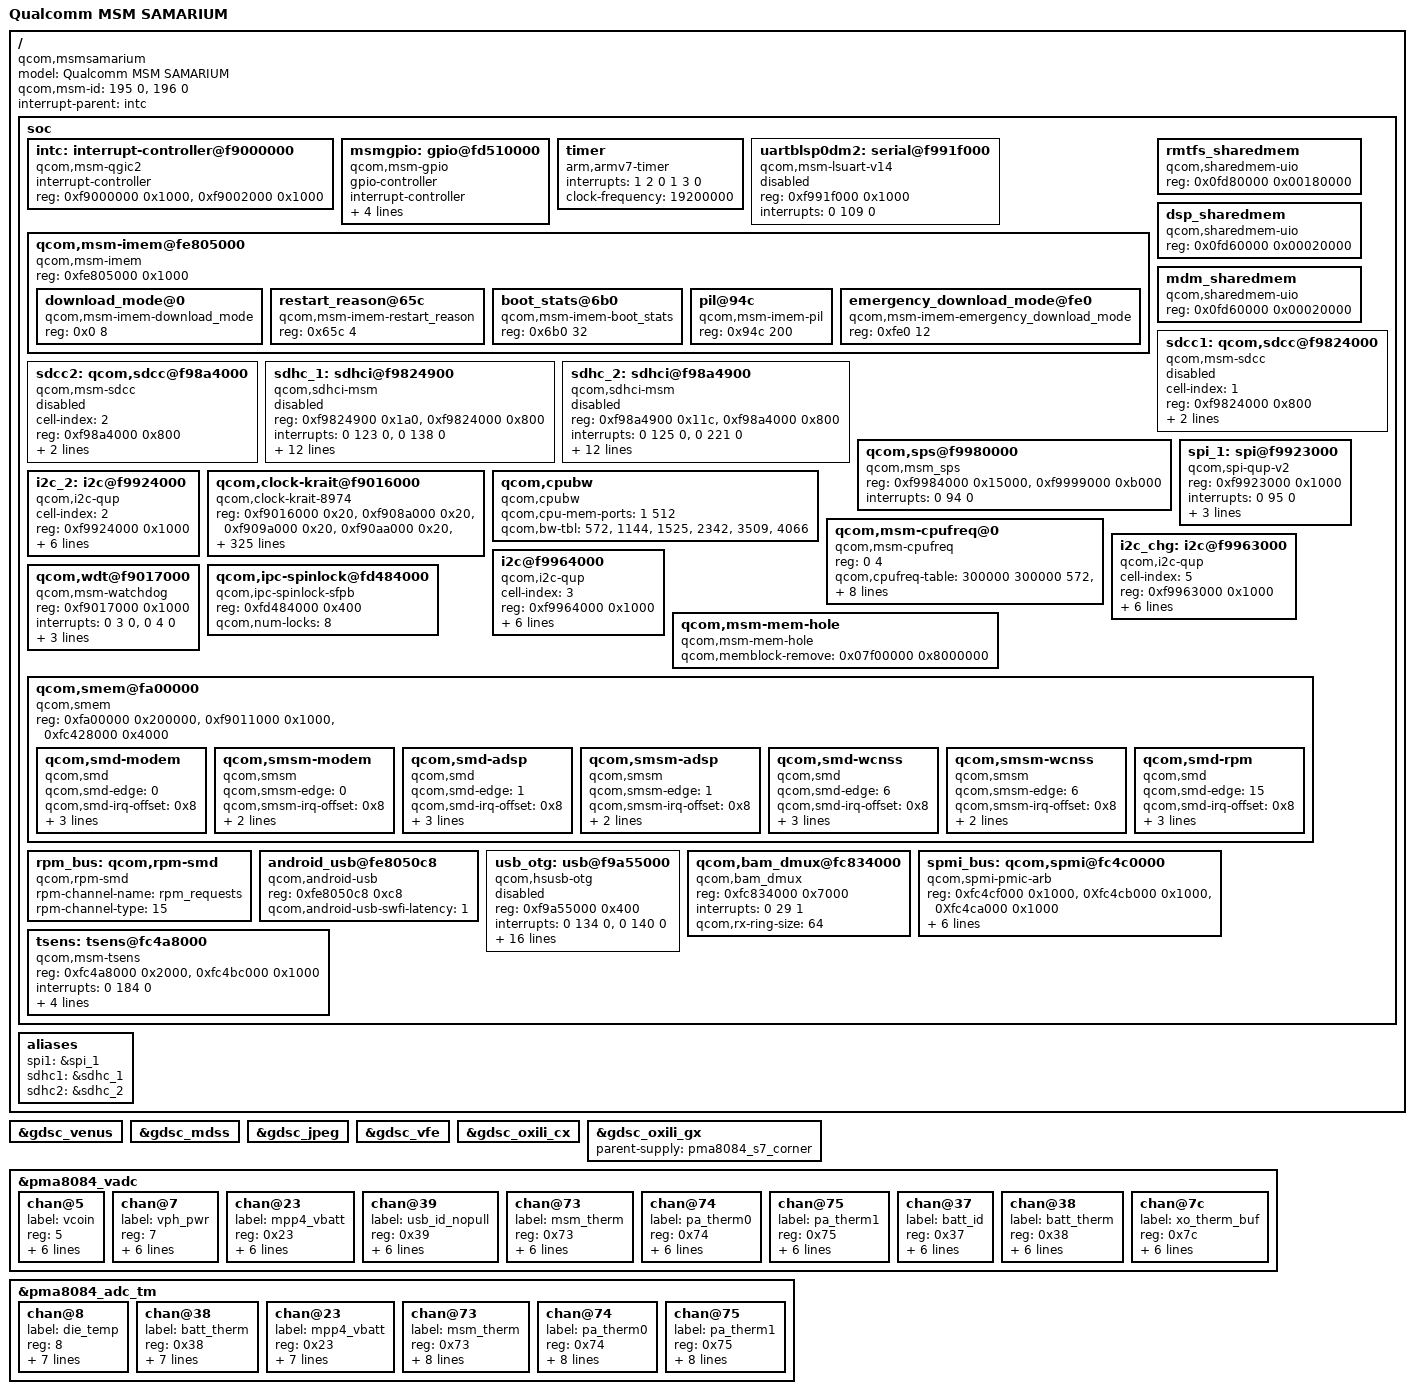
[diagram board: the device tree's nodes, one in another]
/* Copyright (c) 2013-2014, The Linux Foundation. All rights reserved.
 *
 * This program is free software; you can redistribute it and/or modify
 * it under the terms of the GNU General Public License version 2 and
 * only version 2 as published by the Free Software Foundation.
 *
 * This program is distributed in the hope that it will be useful,
 * but WITHOUT ANY WARRANTY; without even the implied warranty of
 * MERCHANTABILITY or FITNESS FOR A PARTICULAR PURPOSE.  See the
 * GNU General Public License for more details.
 */

#include "skeleton.dtsi"

/ {
	model = "Qualcomm MSM SAMARIUM";
	compatible = "qcom,msmsamarium";
	qcom,msm-id = <195 0>,
		      <196 0>;
	interrupt-parent = <&intc>;
	soc: soc { };
	aliases {
		spi1 = &spi_1;
		sdhc1 = &sdhc_1; /* SDC1 eMMC slot */
		sdhc2 = &sdhc_2; /* SDC2 SD card slot */
	};

};

#include "msm-gdsc.dtsi"
#include "msmsamarium-ion.dtsi"
#include "msmsamarium-iommu.dtsi"
#include "msmsamarium-smp2p.dtsi"
#include "msmsamarium-pm.dtsi"
#include "msmsamarium-coresight.dtsi"
#include "msmsamarium-pinctrl.dtsi"
#include "msmsamarium-bus.dtsi"
#include "msmsamarium-gpu.dtsi"
#include "msmsamarium-iommu-domains.dtsi"

&soc {
	#address-cells = <1>;
	#size-cells = <1>;
	ranges;

	intc: interrupt-controller@f9000000 {
		compatible = "qcom,msm-qgic2";
		interrupt-controller;
		#interrupt-cells = <3>;
		reg = <0xf9000000 0x1000>,
		      <0xf9002000 0x1000>;
	};

	msmgpio: gpio@fd510000 {
		compatible = "qcom,msm-gpio";
		gpio-controller;
		#gpio-cells = <2>;
		interrupt-controller;
		#interrupt-cells = <2>;
		reg = <0xfd510000 0x4000>;
		ngpio = <146>;
		interrupts = <0 208 0>;
		qcom,direct-connect-irqs = <8>;
	};

	timer {
		compatible = "arm,armv7-timer";
		interrupts = <1 2 0 1 3 0>;
		clock-frequency = <19200000>;
	};

	uartblsp0dm2: serial@f991f000 {
		compatible = "qcom,msm-lsuart-v14";
		reg = <0xf991f000 0x1000>;
		interrupts = <0 109 0>;
		status = "disabled";
	};

	qcom,msm-imem@fe805000 {
		compatible = "qcom,msm-imem";
		reg = <0xfe805000 0x1000>; /* Address and size of IMEM */
		ranges = <0x0 0xfe805000 0x1000>;
		#address-cells = <1>;
		#size-cells = <1>;

		download_mode@0 {
			compatible = "qcom,msm-imem-download_mode";
			reg = <0x0 8>;
		};

		restart_reason@65c {
			compatible = "qcom,msm-imem-restart_reason";
			reg = <0x65c 4>;
		};

		boot_stats@6b0 {
			compatible = "qcom,msm-imem-boot_stats";
			reg = <0x6b0 32>;
		};

		pil@94c {
			compatible = "qcom,msm-imem-pil";
			reg = <0x94c 200>;
		};

		emergency_download_mode@fe0 {
			compatible = "qcom,msm-imem-emergency_download_mode";
			reg = <0xfe0 12>;
		};
	};

	rmtfs_sharedmem {
		compatible = "qcom,sharedmem-uio";
		reg = <0x0fd80000 0x00180000>;
		reg-names = "rmtfs";
	};

	dsp_sharedmem {
		compatible = "qcom,sharedmem-uio";
		reg = <0x0fd60000 0x00020000>;
		reg-names = "rfsa_dsp";
	};

	mdm_sharedmem {
		compatible = "qcom,sharedmem-uio";
		reg = <0x0fd60000 0x00020000>;
		reg-names = "rfsa_mdm";
	};

	sdcc1: qcom,sdcc@f9824000 {
		cell-index = <1>; /* SDC1 eMMC slot */
		compatible = "qcom,msm-sdcc";
		reg = <0xf9824000 0x800>;
		reg-names = "core_mem";
		interrupts = <0 123 0>;
		interrupt-names = "core_irq";

		qcom,bus-width = <8>;
		status = "disabled";
	};

	sdcc2: qcom,sdcc@f98a4000 {
		cell-index = <2>; /* SDC2 SD card slot */
		compatible = "qcom,msm-sdcc";
		reg = <0xf98a4000 0x800>;
		reg-names = "core_mem";
		interrupts = <0 125 0>;
		interrupt-names = "core_irq";

		qcom,bus-width = <4>;
		status = "disabled";
	};

	sdhc_1: sdhci@f9824900 {
		compatible = "qcom,sdhci-msm";
		reg = <0xf9824900 0x1a0>, <0xf9824000 0x800>;
		reg-names = "hc_mem", "core_mem";
		interrupts = <0 123 0>, <0 138 0>;
		interrupt-names = "hc_irq", "pwr_irq";

		qcom,bus-width = <8>;
		qcom,cpu-dma-latency-us = <200>;

		qcom,msm-bus,name = "sdhc1";
		qcom,msm-bus,num-cases = <8>;
		qcom,msm-bus,num-paths = <1>;
		qcom,msm-bus,vectors-KBps = <78 512 0 0>, /* No vote */
				<78 512 1600 3200>,    /* 400 KB/s*/
				<78 512 80000 160000>, /* 20 MB/s */
				<78 512 100000 200000>, /* 25 MB/s */
				<78 512 200000 400000>, /* 50 MB/s */
				<78 512 400000 800000>, /* 100 MB/s */
				<78 512 400000 800000>, /* 200 MB/s */
				<78 512 2048000 4096000>; /* Max. bandwidth */
		qcom,bus-bw-vectors-bps = <0 400000 20000000 25000000 50000000
						100000000 200000000 4294967295>;

		status = "disabled";
	};

	sdhc_2: sdhci@f98a4900 {
		compatible = "qcom,sdhci-msm";
		reg = <0xf98a4900 0x11c>, <0xf98a4000 0x800>;
		reg-names = "hc_mem", "core_mem";
		interrupts = <0 125 0>, <0 221 0>;
		interrupt-names = "hc_irq", "pwr_irq";

		qcom,bus-width = <4>;
		qcom,cpu-dma-latency-us = <200>;

		qcom,msm-bus,name = "sdhc2";
		qcom,msm-bus,num-cases = <8>;
		qcom,msm-bus,num-paths = <1>;
		qcom,msm-bus,vectors-KBps = <81 512 0 0>, /* No vote */
				<81 512 1600 3200>,    /* 400 KB/s*/
				<81 512 80000 160000>, /* 20 MB/s */
				<81 512 100000 200000>, /* 25 MB/s */
				<81 512 200000 400000>, /* 50 MB/s */
				<81 512 400000 800000>, /* 100 MB/s */
				<81 512 400000 800000>, /* 200 MB/s */
				<81 512 2048000 4096000>; /* Max. bandwidth */
		qcom,bus-bw-vectors-bps = <0 400000 20000000 25000000 50000000
						100000000 200000000 4294967295>;

		status = "disabled";
	};

	qcom,sps@f9980000 {
		compatible = "qcom,msm_sps";
		reg = <0xf9984000 0x15000>,
		      <0xf9999000 0xb000>;
		reg-names = "bam_mem", "core_mem";
		interrupts = <0 94 0>;
	};

	spi_1: spi@f9923000 {
		compatible = "qcom,spi-qup-v2";
		reg = <0xf9923000 0x1000>;
		interrupts = <0 95 0>;
		spi-max-frequency = <19200000>;
		#address-cells = <1>;
		#size-cells = <0>;
		gpios = <&msmgpio 3 0>, /* CLK  */
			<&msmgpio 1 0>, /* MISO */
			<&msmgpio 0 0>; /* MOSI */
		cs-gpios = <&msmgpio 9 0>;
	};

	i2c_2: i2c@f9924000 { /* BLSP1 QUP2 */
		cell-index = <2>;
		compatible = "qcom,i2c-qup";
		#address-cells = <1>;
		#size-cells = <0>;
		reg-names = "qup_phys_addr";
		reg = <0xf9924000 0x1000>;
		interrupt-names = "qup_err_intr";
		interrupts = <0 96 0>;
		qcom,i2c-bus-freq = <384000>;
		qcom,i2c-src-freq = <19200000>;
		qcom,sda-gpio = <&msmgpio 6 0>;
		qcom,scl-gpio = <&msmgpio 7 0>;
		qcom,master-id = <86>;
	};

	qcom,clock-krait@f9016000 {
		compatible = "qcom,clock-krait-8974";
		reg = <0xf9016000 0x20>,
			<0xf908a000 0x20>,
			<0xf909a000 0x20>,
			<0xf90aa000 0x20>,
			<0xf90ba000 0x20>,
			<0xfc4b80b0 0x08>,
			<0xf9011000 0x50>;
		reg-names = "hfpll_l2_clk", "hfpll0_clk",
				"hfpll1_clk", "hfpll2_clk",
				"hfpll3_clk", "efuse", "meas";
		cpu0-supply = <&pma8084_s8>;
		cpu1-supply = <&pma8084_s9>;
		cpu2-supply = <&pma8084_s10>;
		cpu3-supply = <&pma8084_s11>;
		l2-dig-supply = <&pma8084_s2_corner_ao>;
		hfpll-dig-supply = <&pma8084_s2_corner_ao>;
		hfpll-analog-supply = <&pma8084_l12_ao>;
		qcom,hfpll-config-val = <0x7805C665>;

		qcom,l2-fmax =
			<          0 0			 >,
			<  384000000 4 /* SVS_SOC */	 >,
			<  691200000 5 /* NOMINAL */	 >,
			< 1190400000 7 /* SUPER_TURBO */ >;

		qcom,speed0-pvs0-bin-v0 =
			<          0       0    0 >,
			<  300000000  975000    0 >,
			<  384000000  975000    0 >,
			<  480000000  985000    0 >,
			<  595200000 1005000    0 >,
			<  691200000 1025000    0 >,
			<  806400000 1045000    0 >,
			<  921600000 1065000    0 >,
			< 1017600000 1085000    0 >,
			< 1132800000 1105000    0 >,
			< 1248000000 1125000    0 >,
			< 1344000000 1150000    0 >,
			< 1459200000 1175000    0 >,
			< 1555200000 1200000    0 >,
			< 1670400000 1225000    0 >,
			< 1728000000 1250000    0 >;

		qcom,speed2-pvs0-bin-v0 =
			<          0       0    0 >,
			<  300000000  975000    0 >,
			<  384000000  975000    0 >,
			<  480000000  975000    0 >,
			<  595200000  980000    0 >,
			<  691200000 1000000    0 >,
			<  806400000 1020000    0 >,
			<  921600000 1040000    0 >,
			< 1017600000 1060000    0 >,
			< 1132800000 1080000    0 >,
			< 1248000000 1100000    0 >,
			< 1344000000 1125000    0 >,
			< 1459200000 1150000    0 >,
			< 1555200000 1175000    0 >,
			< 1670400000 1200000    0 >,
			< 1728000000 1225000    0 >,
			< 1785600000 1225000    0 >,
			< 1881600000 1250000    0 >;

		qcom,speed2-pvs1-bin-v0 =
			<          0       0    0 >,
			<  300000000  975000    0 >,
			<  384000000  975000    0 >,
			<  480000000  975000    0 >,
			<  595200000  975000    0 >,
			<  691200000  990000    0 >,
			<  806400000 1010000    0 >,
			<  921600000 1030000    0 >,
			< 1017600000 1050000    0 >,
			< 1132800000 1070000    0 >,
			< 1248000000 1090000    0 >,
			< 1344000000 1115000    0 >,
			< 1459200000 1140000    0 >,
			< 1555200000 1165000    0 >,
			< 1670400000 1190000    0 >,
			< 1728000000 1215000    0 >,
			< 1785600000 1215000    0 >,
			< 1881600000 1240000    0 >;

		qcom,speed2-pvs2-bin-v0 =
			<          0       0    0 >,
			<  300000000  950000    0 >,
			<  384000000  950000    0 >,
			<  480000000  950000    0 >,
			<  595200000  960000    0 >,
			<  691200000  980000    0 >,
			<  806400000 1000000    0 >,
			<  921600000 1020000    0 >,
			< 1017600000 1040000    0 >,
			< 1132800000 1060000    0 >,
			< 1248000000 1080000    0 >,
			< 1344000000 1105000    0 >,
			< 1459200000 1130000    0 >,
			< 1555200000 1155000    0 >,
			< 1670400000 1180000    0 >,
			< 1728000000 1205000    0 >,
			< 1785600000 1205000    0 >,
			< 1881600000 1230000    0 >;

		qcom,speed2-pvs3-bin-v0 =
			<          0       0    0 >,
			<  300000000  950000    0 >,
			<  384000000  950000    0 >,
			<  480000000  950000    0 >,
			<  595200000  950000    0 >,
			<  691200000  970000    0 >,
			<  806400000  990000    0 >,
			<  921600000 1010000    0 >,
			< 1017600000 1030000    0 >,
			< 1132800000 1050000    0 >,
			< 1248000000 1070000    0 >,
			< 1344000000 1095000    0 >,
			< 1459200000 1120000    0 >,
			< 1555200000 1145000    0 >,
			< 1670400000 1170000    0 >,
			< 1728000000 1195000    0 >,
			< 1785600000 1195000    0 >,
			< 1881600000 1220000    0 >;

		qcom,speed2-pvs4-bin-v0 =
			<          0       0    0 >,
			<  300000000  950000    0 >,
			<  384000000  950000    0 >,
			<  480000000  950000    0 >,
			<  595200000  950000    0 >,
			<  691200000  960000    0 >,
			<  806400000  980000    0 >,
			<  921600000 1000000    0 >,
			< 1017600000 1020000    0 >,
			< 1132800000 1040000    0 >,
			< 1248000000 1060000    0 >,
			< 1344000000 1085000    0 >,
			< 1459200000 1110000    0 >,
			< 1555200000 1135000    0 >,
			< 1670400000 1160000    0 >,
			< 1728000000 1185000    0 >,
			< 1785600000 1185000    0 >,
			< 1881600000 1210000    0 >;

		qcom,speed2-pvs5-bin-v0 =
			<          0       0    0 >,
			<  300000000  950000    0 >,
			<  384000000  950000    0 >,
			<  480000000  950000    0 >,
			<  595200000  950000    0 >,
			<  691200000  950000    0 >,
			<  806400000  970000    0 >,
			<  921600000  990000    0 >,
			< 1017600000 1010000    0 >,
			< 1132800000 1030000    0 >,
			< 1248000000 1050000    0 >,
			< 1344000000 1075000    0 >,
			< 1459200000 1100000    0 >,
			< 1555200000 1125000    0 >,
			< 1670400000 1150000    0 >,
			< 1728000000 1175000    0 >,
			< 1785600000 1175000    0 >,
			< 1881600000 1200000    0 >;

		qcom,speed2-pvs6-bin-v0 =
			<          0       0    0 >,
			<  300000000  925000    0 >,
			<  384000000  925000    0 >,
			<  480000000  925000    0 >,
			<  595200000  925000    0 >,
			<  691200000  940000    0 >,
			<  806400000  960000    0 >,
			<  921600000  980000    0 >,
			< 1017600000 1000000    0 >,
			< 1132800000 1020000    0 >,
			< 1248000000 1040000    0 >,
			< 1344000000 1065000    0 >,
			< 1459200000 1090000    0 >,
			< 1555200000 1115000    0 >,
			< 1670400000 1140000    0 >,
			< 1728000000 1165000    0 >,
			< 1785600000 1165000    0 >,
			< 1881600000 1190000    0 >;

		qcom,speed2-pvs7-bin-v0 =
			<          0       0    0 >,
			<  300000000  925000    0 >,
			<  384000000  925000    0 >,
			<  480000000  925000    0 >,
			<  595200000  925000    0 >,
			<  691200000  930000    0 >,
			<  806400000  950000    0 >,
			<  921600000  970000    0 >,
			< 1017600000  990000    0 >,
			< 1132800000 1010000    0 >,
			< 1248000000 1030000    0 >,
			< 1344000000 1055000    0 >,
			< 1459200000 1080000    0 >,
			< 1555200000 1105000    0 >,
			< 1670400000 1130000    0 >,
			< 1728000000 1155000    0 >,
			< 1785600000 1155000    0 >,
			< 1881600000 1180000    0 >;

		qcom,speed2-pvs8-bin-v0 =
			<          0       0    0 >,
			<  300000000  925000    0 >,
			<  384000000  925000    0 >,
			<  480000000  925000    0 >,
			<  595200000  925000    0 >,
			<  691200000  925000    0 >,
			<  806400000  940000    0 >,
			<  921600000  960000    0 >,
			< 1017600000  980000    0 >,
			< 1132800000 1000000    0 >,
			< 1248000000 1020000    0 >,
			< 1344000000 1045000    0 >,
			< 1459200000 1070000    0 >,
			< 1555200000 1095000    0 >,
			< 1670400000 1120000    0 >,
			< 1728000000 1145000    0 >,
			< 1785600000 1145000    0 >,
			< 1881600000 1170000    0 >;

		qcom,speed2-pvs9-bin-v0 =
			<          0       0    0 >,
			<  300000000  900000    0 >,
			<  384000000  900000    0 >,
			<  480000000  900000    0 >,
			<  595200000  900000    0 >,
			<  691200000  910000    0 >,
			<  806400000  930000    0 >,
			<  921600000  950000    0 >,
			< 1017600000  970000    0 >,
			< 1132800000  990000    0 >,
			< 1248000000 1010000    0 >,
			< 1344000000 1035000    0 >,
			< 1459200000 1060000    0 >,
			< 1555200000 1085000    0 >,
			< 1670400000 1110000    0 >,
			< 1728000000 1135000    0 >,
			< 1785600000 1135000    0 >,
			< 1881600000 1160000    0 >;

		qcom,speed2-pvs10-bin-v0 =
			<          0       0    0 >,
			<  300000000  900000    0 >,
			<  384000000  900000    0 >,
			<  480000000  900000    0 >,
			<  595200000  900000    0 >,
			<  691200000  900000    0 >,
			<  806400000  920000    0 >,
			<  921600000  940000    0 >,
			< 1017600000  960000    0 >,
			< 1132800000  980000    0 >,
			< 1248000000 1000000    0 >,
			< 1344000000 1025000    0 >,
			< 1459200000 1050000    0 >,
			< 1555200000 1075000    0 >,
			< 1670400000 1100000    0 >,
			< 1728000000 1125000    0 >,
			< 1785600000 1125000    0 >,
			< 1881600000 1150000    0 >;

		qcom,speed2-pvs11-bin-v0 =
			<          0       0    0 >,
			<  300000000  900000    0 >,
			<  384000000  900000    0 >,
			<  480000000  900000    0 >,
			<  595200000  900000    0 >,
			<  691200000  900000    0 >,
			<  806400000  910000    0 >,
			<  921600000  930000    0 >,
			< 1017600000  950000    0 >,
			< 1132800000  970000    0 >,
			< 1248000000  990000    0 >,
			< 1344000000 1015000    0 >,
			< 1459200000 1040000    0 >,
			< 1555200000 1065000    0 >,
			< 1670400000 1090000    0 >,
			< 1728000000 1115000    0 >,
			< 1785600000 1115000    0 >,
			< 1881600000 1140000    0 >;

		qcom,speed2-pvs12-bin-v0 =
			<          0       0    0 >,
			<  300000000  875000    0 >,
			<  384000000  875000    0 >,
			<  480000000  875000    0 >,
			<  595200000  875000    0 >,
			<  691200000  880000    0 >,
			<  806400000  900000    0 >,
			<  921600000  920000    0 >,
			< 1017600000  940000    0 >,
			< 1132800000  960000    0 >,
			< 1248000000  980000    0 >,
			< 1344000000 1005000    0 >,
			< 1459200000 1030000    0 >,
			< 1555200000 1055000    0 >,
			< 1670400000 1080000    0 >,
			< 1728000000 1105000    0 >,
			< 1785600000 1105000    0 >,
			< 1881600000 1130000    0 >;

		qcom,speed2-pvs13-bin-v0 =
			<          0       0    0 >,
			<  300000000  875000    0 >,
			<  384000000  875000    0 >,
			<  480000000  875000    0 >,
			<  595200000  875000    0 >,
			<  691200000  875000    0 >,
			<  806400000  890000    0 >,
			<  921600000  910000    0 >,
			< 1017600000  930000    0 >,
			< 1132800000  950000    0 >,
			< 1248000000  970000    0 >,
			< 1344000000  995000    0 >,
			< 1459200000 1020000    0 >,
			< 1555200000 1045000    0 >,
			< 1670400000 1070000    0 >,
			< 1728000000 1095000    0 >,
			< 1785600000 1095000    0 >,
			< 1881600000 1120000    0 >;

		qcom,speed2-pvs14-bin-v0 =
			<          0       0    0 >,
			<  300000000  875000    0 >,
			<  384000000  875000    0 >,
			<  480000000  875000    0 >,
			<  595200000  875000    0 >,
			<  691200000  875000    0 >,
			<  806400000  880000    0 >,
			<  921600000  900000    0 >,
			< 1017600000  920000    0 >,
			< 1132800000  940000    0 >,
			< 1248000000  960000    0 >,
			< 1344000000  985000    0 >,
			< 1459200000 1010000    0 >,
			< 1555200000 1035000    0 >,
			< 1670400000 1060000    0 >,
			< 1728000000 1085000    0 >,
			< 1785600000 1085000    0 >,
			< 1881600000 1110000    0 >;

		qcom,speed2-pvs15-bin-v0 =
			<          0       0    0 >,
			<  300000000  875000    0 >,
			<  384000000  875000    0 >,
			<  480000000  875000    0 >,
			<  595200000  875000    0 >,
			<  691200000  875000    0 >,
			<  806400000  875000    0 >,
			<  921600000  890000    0 >,
			< 1017600000  910000    0 >,
			< 1132800000  930000    0 >,
			< 1248000000  950000    0 >,
			< 1344000000  975000    0 >,
			< 1459200000 1000000    0 >,
			< 1555200000 1025000    0 >,
			< 1670400000 1050000    0 >,
			< 1728000000 1075000    0 >,
			< 1785600000 1075000    0 >,
			< 1881600000 1100000    0 >;

		qcom,speed1-pvs0-bin-v0 =
			<          0       0    0 >,
			<  300000000  975000    0 >,
			<  384000000  975000    0 >,
			<  480000000  985000    0 >,
			<  595200000 1005000    0 >,
			<  691200000 1025000    0 >,
			<  806400000 1045000    0 >,
			<  921600000 1065000    0 >,
			< 1017600000 1085000    0 >,
			< 1132800000 1105000    0 >,
			< 1248000000 1125000    0 >,
			< 1344000000 1150000    0 >,
			< 1459200000 1175000    0 >,
			< 1555200000 1200000    0 >,
			< 1670400000 1225000    0 >,
			< 1728000000 1250000    0 >;

		qcom,speed1-pvs1-bin-v0 =
			<          0       0    0 >,
			<  300000000  975000    0 >,
			<  384000000  975000    0 >,
			<  480000000  975000    0 >,
			<  595200000  990000    0 >,
			<  691200000 1010000    0 >,
			<  806400000 1030000    0 >,
			<  921600000 1050000    0 >,
			< 1017600000 1070000    0 >,
			< 1132800000 1090000    0 >,
			< 1248000000 1110000    0 >,
			< 1344000000 1135000    0 >,
			< 1459200000 1160000    0 >,
			< 1555200000 1185000    0 >,
			< 1670400000 1210000    0 >,
			< 1728000000 1235000    0 >;

		qcom,speed1-pvs2-bin-v0 =
			<          0       0    0 >,
			<  300000000  950000    0 >,
			<  384000000  950000    0 >,
			<  480000000  955000    0 >,
			<  595200000  975000    0 >,
			<  691200000  995000    0 >,
			<  806400000 1015000    0 >,
			<  921600000 1035000    0 >,
			< 1017600000 1055000    0 >,
			< 1132800000 1075000    0 >,
			< 1248000000 1095000    0 >,
			< 1344000000 1120000    0 >,
			< 1459200000 1145000    0 >,
			< 1555200000 1170000    0 >,
			< 1670400000 1195000    0 >,
			< 1728000000 1220000    0 >;

		qcom,speed1-pvs3-bin-v0 =
			<          0       0    0 >,
			<  300000000  950000    0 >,
			<  384000000  950000    0 >,
			<  480000000  950000    0 >,
			<  595200000  960000    0 >,
			<  691200000  980000    0 >,
			<  806400000 1000000    0 >,
			<  921600000 1020000    0 >,
			< 1017600000 1040000    0 >,
			< 1132800000 1060000    0 >,
			< 1248000000 1080000    0 >,
			< 1344000000 1105000    0 >,
			< 1459200000 1130000    0 >,
			< 1555200000 1155000    0 >,
			< 1670400000 1180000    0 >,
			< 1728000000 1205000    0 >;

		qcom,speed1-pvs4-bin-v0 =
			<          0       0    0 >,
			<  300000000  950000    0 >,
			<  384000000  950000    0 >,
			<  480000000  950000    0 >,
			<  595200000  950000    0 >,
			<  691200000  965000    0 >,
			<  806400000  985000    0 >,
			<  921600000 1005000    0 >,
			< 1017600000 1025000    0 >,
			< 1132800000 1045000    0 >,
			< 1248000000 1065000    0 >,
			< 1344000000 1090000    0 >,
			< 1459200000 1115000    0 >,
			< 1555200000 1140000    0 >,
			< 1670400000 1165000    0 >,
			< 1728000000 1190000    0 >;

		qcom,speed1-pvs5-bin-v0 =
			<          0       0    0 >,
			<  300000000  950000    0 >,
			<  384000000  950000    0 >,
			<  480000000  950000    0 >,
			<  595200000  950000    0 >,
			<  691200000  950000    0 >,
			<  806400000  970000    0 >,
			<  921600000  990000    0 >,
			< 1017600000 1010000    0 >,
			< 1132800000 1030000    0 >,
			< 1248000000 1050000    0 >,
			< 1344000000 1075000    0 >,
			< 1459200000 1100000    0 >,
			< 1555200000 1125000    0 >,
			< 1670400000 1150000    0 >,
			< 1728000000 1175000    0 >;

		qcom,speed1-pvs6-bin-v0 =
			<          0       0    0 >,
			<  300000000  925000    0 >,
			<  384000000  925000    0 >,
			<  480000000  925000    0 >,
			<  595200000  925000    0 >,
			<  691200000  935000    0 >,
			<  806400000  955000    0 >,
			<  921600000  975000    0 >,
			< 1017600000  995000    0 >,
			< 1132800000 1015000    0 >,
			< 1248000000 1035000    0 >,
			< 1344000000 1060000    0 >,
			< 1459200000 1085000    0 >,
			< 1555200000 1110000    0 >,
			< 1670400000 1135000    0 >,
			< 1728000000 1160000    0 >;

		qcom,speed1-pvs7-bin-v0 =
			<          0       0    0 >,
			<  300000000  925000    0 >,
			<  384000000  925000    0 >,
			<  480000000  925000    0 >,
			<  595200000  925000    0 >,
			<  691200000  925000    0 >,
			<  806400000  940000    0 >,
			<  921600000  960000    0 >,
			< 1017600000  980000    0 >,
			< 1132800000 1000000    0 >,
			< 1248000000 1020000    0 >,
			< 1344000000 1045000    0 >,
			< 1459200000 1070000    0 >,
			< 1555200000 1095000    0 >,
			< 1670400000 1120000    0 >,
			< 1728000000 1145000    0 >;

		qcom,speed1-pvs8-bin-v0 =
			<          0       0    0 >,
			<  300000000  925000    0 >,
			<  384000000  925000    0 >,
			<  480000000  925000    0 >,
			<  595200000  925000    0 >,
			<  691200000  925000    0 >,
			<  806400000  925000    0 >,
			<  921600000  945000    0 >,
			< 1017600000  965000    0 >,
			< 1132800000  985000    0 >,
			< 1248000000 1005000    0 >,
			< 1344000000 1030000    0 >,
			< 1459200000 1055000    0 >,
			< 1555200000 1080000    0 >,
			< 1670400000 1105000    0 >,
			< 1728000000 1130000    0 >;

		qcom,speed1-pvs9-bin-v0 =
			<          0       0    0 >,
			<  300000000  900000    0 >,
			<  384000000  900000    0 >,
			<  480000000  900000    0 >,
			<  595200000  900000    0 >,
			<  691200000  900000    0 >,
			<  806400000  910000    0 >,
			<  921600000  930000    0 >,
			< 1017600000  950000    0 >,
			< 1132800000  970000    0 >,
			< 1248000000  990000    0 >,
			< 1344000000 1015000    0 >,
			< 1459200000 1040000    0 >,
			< 1555200000 1065000    0 >,
			< 1670400000 1090000    0 >,
			< 1728000000 1115000    0 >;

		qcom,speed1-pvs10-bin-v0 =
			<          0       0    0 >,
			<  300000000  900000    0 >,
			<  384000000  900000    0 >,
			<  480000000  900000    0 >,
			<  595200000  900000    0 >,
			<  691200000  900000    0 >,
			<  806400000  900000    0 >,
			<  921600000  915000    0 >,
			< 1017600000  935000    0 >,
			< 1132800000  955000    0 >,
			< 1248000000  975000    0 >,
			< 1344000000 1000000    0 >,
			< 1459200000 1025000    0 >,
			< 1555200000 1050000    0 >,
			< 1670400000 1075000    0 >,
			< 1728000000 1100000    0 >;

		qcom,speed1-pvs11-bin-v0 =
			<          0       0    0 >,
			<  300000000  900000    0 >,
			<  384000000  900000    0 >,
			<  480000000  900000    0 >,
			<  595200000  900000    0 >,
			<  691200000  900000    0 >,
			<  806400000  900000    0 >,
			<  921600000  900000    0 >,
			< 1017600000  920000    0 >,
			< 1132800000  940000    0 >,
			< 1248000000  960000    0 >,
			< 1344000000  985000    0 >,
			< 1459200000 1010000    0 >,
			< 1555200000 1035000    0 >,
			< 1670400000 1060000    0 >,
			< 1728000000 1085000    0 >;

		qcom,speed1-pvs12-bin-v0 =
			<          0       0    0 >,
			<  300000000  875000    0 >,
			<  384000000  875000    0 >,
			<  480000000  875000    0 >,
			<  595200000  875000    0 >,
			<  691200000  875000    0 >,
			<  806400000  875000    0 >,
			<  921600000  885000    0 >,
			< 1017600000  905000    0 >,
			< 1132800000  925000    0 >,
			< 1248000000  945000    0 >,
			< 1344000000  970000    0 >,
			< 1459200000  995000    0 >,
			< 1555200000 1020000    0 >,
			< 1670400000 1045000    0 >,
			< 1728000000 1070000    0 >;

		qcom,speed1-pvs13-bin-v0 =
			<          0       0    0 >,
			<  300000000  875000    0 >,
			<  384000000  875000    0 >,
			<  480000000  875000    0 >,
			<  595200000  875000    0 >,
			<  691200000  875000    0 >,
			<  806400000  875000    0 >,
			<  921600000  875000    0 >,
			< 1017600000  890000    0 >,
			< 1132800000  910000    0 >,
			< 1248000000  930000    0 >,
			< 1344000000  955000    0 >,
			< 1459200000  980000    0 >,
			< 1555200000 1005000    0 >,
			< 1670400000 1030000    0 >,
			< 1728000000 1055000    0 >;

		qcom,speed1-pvs14-bin-v0 =
			<          0       0    0 >,
			<  300000000  875000    0 >,
			<  384000000  875000    0 >,
			<  480000000  875000    0 >,
			<  595200000  875000    0 >,
			<  691200000  875000    0 >,
			<  806400000  875000    0 >,
			<  921600000  875000    0 >,
			< 1017600000  875000    0 >,
			< 1132800000  895000    0 >,
			< 1248000000  915000    0 >,
			< 1344000000  940000    0 >,
			< 1459200000  965000    0 >,
			< 1555200000  990000    0 >,
			< 1670400000 1015000    0 >,
			< 1728000000 1040000    0 >;

		qcom,speed1-pvs15-bin-v0 =
			<          0       0    0 >,
			<  300000000  875000    0 >,
			<  384000000  875000    0 >,
			<  480000000  875000    0 >,
			<  595200000  875000    0 >,
			<  691200000  875000    0 >,
			<  806400000  875000    0 >,
			<  921600000  875000    0 >,
			< 1017600000  875000    0 >,
			< 1132800000  880000    0 >,
			< 1248000000  900000    0 >,
			< 1344000000  925000    0 >,
			< 1459200000  950000    0 >,
			< 1555200000  975000    0 >,
			< 1670400000 1000000    0 >,
			< 1728000000 1025000    0 >;
	};

	qcom,cpubw {
		compatible = "qcom,cpubw";
		qcom,cpu-mem-ports = <1 512>;
		qcom,bw-tbl =
			<  572 /*  75 MHz */ >,
			< 1144 /* 150 MHz */ >,
			< 1525 /* 200 MHz */ >,
			< 2342 /* 307 MHz */ >,
			< 3509 /* 460 MHz */ >,
			< 4066 /* 533 MHz */ >;
	};

	qcom,msm-cpufreq@0 {
		reg = <0 4>;
		compatible = "qcom,msm-cpufreq";
		qcom,cpufreq-table =
			<  300000  300000  572 >,
			<  384000  384000  572 >,
			<  480000  480000 1144 >,
			<  595200  595200 1525 >,
			<  691200  691200 2342 >,
			<  806400  806400 2342 >,
			<  921600  921600 3509 >,
			< 1017600 1017600 3509 >,
			< 1132800 1190400 3509 >,
			< 1248000 1190400 4066 >,
			< 1344000 1190400 4066 >,
			< 1459200 1190400 4066 >,
			< 1555200 1190400 4066 >,
			< 1670400 1190400 4066 >,
			< 1728000 1190400 4066 >,
			< 1785600 1190400 4066 >,
			< 1881600 1190400 4066 >;
	};

	i2c_chg: i2c@f9963000 { /* BLSP2 QUP1 */
		cell-index = <5>;
		compatible = "qcom,i2c-qup";
		#address-cells = <1>;
		#size-cells = <0>;
		reg-names = "qup_phys_addr";
		reg = <0xf9963000 0x1000>;
		interrupt-names = "qup_err_intr";
		interrupts = <0 101 0>;
		qcom,i2c-bus-freq = <100000>;
		qcom,i2c-src-freq = <19200000>;
		qcom,sda-gpio = <&msmgpio 55 0>;
		qcom,scl-gpio = <&msmgpio 56 0>;
		qcom,master-id = <84>;
	};

	i2c@f9964000 { /* BLSP-2 QUP-2 */
		cell-index = <3>;
		compatible = "qcom,i2c-qup";
		reg = <0xf9964000 0x1000>;
		#address-cells = <1>;
		#size-cells = <0>;
		reg-names = "qup_phys_addr";
		interrupts = <0 102 0>;
		interrupt-names = "qup_err_intr";
		qcom,i2c-bus-freq = <400000>;
		qcom,i2c-src-freq = <19200000>;
		qcom,sda-gpio = <&msmgpio 87 0>;
		qcom,scl-gpio = <&msmgpio 88 0>;
		qcom,master-id = <84>;
	};

	qcom,wdt@f9017000 {
		compatible = "qcom,msm-watchdog";
		reg = <0xf9017000 0x1000>;
		interrupts = <0 3 0>, <0 4 0>;
		qcom,bark-time = <11000>;
		qcom,pet-time = <10000>;
		qcom,ipi-ping;
	};

	qcom,msm-mem-hole {
		compatible = "qcom,msm-mem-hole";
		qcom,memblock-remove = <0x07f00000 0x8000000>; /* Address and size of hole */
	};

	qcom,ipc-spinlock@fd484000 {
		compatible = "qcom,ipc-spinlock-sfpb";
		reg = <0xfd484000 0x400>;
		qcom,num-locks = <8>;
	};

	qcom,smem@fa00000 {
		compatible = "qcom,smem";
		reg = <0xfa00000 0x200000>,
			<0xf9011000 0x1000>,
			<0xfc428000 0x4000>;
		reg-names = "smem", "irq-reg-base", "aux-mem1";

		qcom,smd-modem {
			compatible = "qcom,smd";
			qcom,smd-edge = <0>;
			qcom,smd-irq-offset = <0x8>;
			qcom,smd-irq-bitmask = <0x1000>;
			qcom,pil-string = "modem";
			interrupts = <0 25 1>;
		};

		qcom,smsm-modem {
			compatible = "qcom,smsm";
			qcom,smsm-edge = <0>;
			qcom,smsm-irq-offset = <0x8>;
			qcom,smsm-irq-bitmask = <0x2000>;
			interrupts = <0 26 1>;
		};

		qcom,smd-adsp {
			compatible = "qcom,smd";
			qcom,smd-edge = <1>;
			qcom,smd-irq-offset = <0x8>;
			qcom,smd-irq-bitmask = <0x100>;
			qcom,pil-string = "adsp";
			interrupts = <0 156 1>;
		};

		qcom,smsm-adsp {
			compatible = "qcom,smsm";
			qcom,smsm-edge = <1>;
			qcom,smsm-irq-offset = <0x8>;
			qcom,smsm-irq-bitmask = <0x200>;
			interrupts = <0 157 1>;
		};

		qcom,smd-wcnss {
			compatible = "qcom,smd";
			qcom,smd-edge = <6>;
			qcom,smd-irq-offset = <0x8>;
			qcom,smd-irq-bitmask = <0x20000>;
			qcom,pil-string = "wcnss";
			interrupts = <0 142 1>;
		};

		qcom,smsm-wcnss {
			compatible = "qcom,smsm";
			qcom,smsm-edge = <6>;
			qcom,smsm-irq-offset = <0x8>;
			qcom,smsm-irq-bitmask = <0x80000>;
			interrupts = <0 144 1>;
		};

		qcom,smd-rpm {
			compatible = "qcom,smd";
			qcom,smd-edge = <15>;
			qcom,smd-irq-offset = <0x8>;
			qcom,smd-irq-bitmask = <0x1>;
			interrupts = <0 168 1>;
			qcom,irq-no-suspend;
		};
	};

	rpm_bus: qcom,rpm-smd {
		compatible = "qcom,rpm-smd";
		rpm-channel-name = "rpm_requests";
		rpm-channel-type = <15>; /* SMD_APPS_RPM */
	};

	android_usb@fe8050c8 {
		compatible = "qcom,android-usb";
		reg = <0xfe8050c8 0xc8>;
		qcom,android-usb-swfi-latency = <1>;
	};

	usb_otg: usb@f9a55000 {
		compatible = "qcom,hsusb-otg";
		status = "disabled";

		reg = <0xf9a55000 0x400>;
		interrupts = <0 134 0>, <0 140 0>;
		interrupt-names = "core_irq", "async_irq";
		HSUSB_VDDCX-supply = "";
		HSUSB_1p8-supply = "";
		HSUSB_3p3-supply = "";
		qcom,vdd-voltage-level = <1 5 7>;

		qcom,hsusb-otg-phy-type = <2>;
		qcom,hsusb-otg-phy-init-seq =
			<0x44 0x80 0x68 0x81 0x24 0x82 0x13 0x83 0xffffffff>;
		qcom,hsusb-otg-mode = <1>;
		qcom,hsusb-otg-otg-control = <1>;
		qcom,hsusb-otg-disable-reset;
		qcom,dp-manual-pullup;

		qcom,msm-bus,name = "usb2";
		qcom,msm-bus,num-cases = <3>;
		qcom,msm-bus,num-paths = <1>;
		qcom,msm-bus,vectors-KBps =
				<87 512 0 0>,
				<87 512 60000 960000>,
				<87 512 6000  6000>;
	};

	qcom,bam_dmux@fc834000 {
		compatible = "qcom,bam_dmux";
		reg = <0xfc834000 0x7000>;
		interrupts = <0 29 1>;
		qcom,rx-ring-size = <64>;
	};

	spmi_bus: qcom,spmi@fc4c0000 {
		compatible = "qcom,spmi-pmic-arb";
		reg = <0xfc4cf000 0x1000>,
		      <0Xfc4cb000 0x1000>,
		      <0Xfc4ca000 0x1000>;
		reg-names = "core", "intr", "cnfg";
		interrupts = <0 190 0>;
		qcom,pmic-arb-channel = <0>;
		qcom,pmic-arb-ee = <0>;
		#interrupt-cells = <3>;
		interrupt-controller;
		#address-cells = <1>;
		#size-cells = <0>;
		cell-index = <0>;
		qcom,not-wakeup;     /* Needed until MPM is fully configured. */
	};

	tsens: tsens@fc4a8000 {
		compatible = "qcom,msm-tsens";
		reg = <0xfc4a8000 0x2000>,
		      <0xfc4bc000 0x1000>;
		reg-names = "tsens_physical", "tsens_eeprom_physical";
		interrupts = <0 184 0>;
		qcom,sensors = <11>;
		qcom,slope = <3200 3200 3200 3200 3200 3200 3200 3200 3200
				3200 3200>;
		qcom,calib-mode = "fuse_map1";
	};
};

&gdsc_venus {
	clock-names = "core_clk";
	status = "ok";
};

&gdsc_mdss {
	clock-names = "core_clk", "lut_clk";
	status = "ok";
};

&gdsc_jpeg {
	status = "ok";
};

&gdsc_vfe {
	clock-names = "core0_clk", "cpp_clk";
	status = "ok";
};

&gdsc_oxili_cx {
	status = "ok";
};

&gdsc_oxili_gx {
	clock-names = "core_clk";
	parent-supply = <&pma8084_s7_corner>;
	status = "ok";
};

#include "msm-pma8084-rpm-regulator.dtsi"
#include "msm-pma8084.dtsi"
#include "msmsamarium-regulator.dtsi"
#include "msmsamarium-mdss.dtsi"

&pma8084_vadc {
	chan@5 {
		label = "vcoin";
		reg = <5>;
		qcom,decimation = <0>;
		qcom,pre-div-channel-scaling = <1>;
		qcom,calibration-type = "absolute";
		qcom,scale-function = <0>;
		qcom,hw-settle-time = <0>;
		qcom,fast-avg-setup = <0>;
	};

	chan@7 {
		label = "vph_pwr";
		reg = <7>;
		qcom,decimation = <0>;
		qcom,pre-div-channel-scaling = <1>;
		qcom,calibration-type = "absolute";
		qcom,scale-function = <0>;
		qcom,hw-settle-time = <0>;
		qcom,fast-avg-setup = <0>;
	};

	chan@23 {
		label = "mpp4_vbatt";
		reg = <0x23>;
		qcom,decimation = <0>;
		qcom,pre-div-channel-scaling = <1>;
		qcom,calibration-type = "absolute";
		qcom,scale-function = <0>;
		qcom,hw-settle-time = <0>;
		qcom,fast-avg-setup = <0>;
	};

	chan@39 {
		label = "usb_id_nopull";
		reg = <0x39>;
		qcom,decimation = <0>;
		qcom,pre-div-channel-scaling = <0>;
		qcom,calibration-type = "ratiometric";
		qcom,scale-function = <0>;
		qcom,hw-settle-time = <2>;
		qcom,fast-avg-setup = <0>;
	};

	chan@73 {
		label = "msm_therm";
		reg = <0x73>;
		qcom,decimation = <0>;
		qcom,pre-div-channel-scaling = <0>;
		qcom,calibration-type = "ratiometric";
		qcom,scale-function = <2>;
		qcom,hw-settle-time = <2>;
		qcom,fast-avg-setup = <0>;
	};

	chan@74 {
		label = "pa_therm0";
		reg = <0x74>;
		qcom,decimation = <0>;
		qcom,pre-div-channel-scaling = <0>;
		qcom,calibration-type = "ratiometric";
		qcom,scale-function = <2>;
		qcom,hw-settle-time = <2>;
		qcom,fast-avg-setup = <0>;
	};

	chan@75 {
		label = "pa_therm1";
		reg = <0x75>;
		qcom,decimation = <0>;
		qcom,pre-div-channel-scaling = <0>;
		qcom,calibration-type = "ratiometric";
		qcom,scale-function = <2>;
		qcom,hw-settle-time = <2>;
		qcom,fast-avg-setup = <0>;
	};

	chan@37 {
		label = "batt_id";
		reg = <0x37>;
		qcom,decimation = <0>;
		qcom,pre-div-channel-scaling = <0>;
		qcom,calibration-type = "ratiometric";
		qcom,scale-function = <0>;
		qcom,hw-settle-time = <2>;
		qcom,fast-avg-setup = <0>;
	};

	chan@38 {
		label = "batt_therm";
		reg = <0x38>;
		qcom,decimation = <0>;
		qcom,pre-div-channel-scaling = <0>;
		qcom,calibration-type = "ratiometric";
		qcom,scale-function = <8>;
		qcom,hw-settle-time = <2>;
		qcom,fast-avg-setup = <0>;
	};

	chan@7c {
		label = "xo_therm_buf";
		reg = <0x7c>;
		qcom,decimation = <0>;
		qcom,pre-div-channel-scaling = <0>;
		qcom,calibration-type = "ratiometric";
		qcom,scale-function = <4>;
		qcom,hw-settle-time = <2>;
		qcom,fast-avg-setup = <0>;
	};
};

&pma8084_adc_tm {
	chan@8 {
		label = "die_temp";
		reg = <8>;
		qcom,decimation = <0>;
		qcom,pre-div-channel-scaling = <0>;
		qcom,calibration-type = "absolute";
		qcom,scale-function = <3>;
		qcom,hw-settle-time = <0>;
		qcom,fast-avg-setup = <3>;
		qcom,btm-channel-number = <0x48>;
	};

	chan@38 {
		label = "batt_therm";
		reg = <0x38>;
		qcom,decimation = <0>;
		qcom,pre-div-channel-scaling = <0>;
		qcom,calibration-type = "ratiometric";
		qcom,scale-function = <1>;
		qcom,hw-settle-time = <2>;
		qcom,fast-avg-setup = <0>;
		qcom,btm-channel-number = <0x68>;
	};

	chan@23 {
		label = "mpp4_vbatt";
		reg = <0x23>;
		qcom,decimation = <0>;
		qcom,pre-div-channel-scaling = <1>;
		qcom,calibration-type = "absolute";
		qcom,scale-function = <0>;
		qcom,hw-settle-time = <0>;
		qcom,fast-avg-setup = <0>;
		qcom,btm-channel-number = <0x70>;
	};

	chan@73 {
		label = "msm_therm";
		reg = <0x73>;
		qcom,decimation = <0>;
		qcom,pre-div-channel-scaling = <0>;
		qcom,calibration-type = "ratiometric";
		qcom,scale-function = <2>;
		qcom,hw-settle-time = <2>;
		qcom,fast-avg-setup = <0>;
		qcom,btm-channel-number = <0x78>;
		qcom,thermal-node;
	};

	chan@74 {
		label = "pa_therm0";
		reg = <0x74>;
		qcom,decimation = <0>;
		qcom,pre-div-channel-scaling = <0>;
		qcom,calibration-type = "ratiometric";
		qcom,scale-function = <2>;
		qcom,hw-settle-time = <2>;
		qcom,fast-avg-setup = <0>;
		qcom,btm-channel-number = <0x80>;
		qcom,thermal-node;
	};

	chan@75 {
		label = "pa_therm1";
		reg = <0x75>;
		qcom,decimation = <0>;
		qcom,pre-div-channel-scaling = <0>;
		qcom,calibration-type = "ratiometric";
		qcom,scale-function = <2>;
		qcom,hw-settle-time = <2>;
		qcom,fast-avg-setup = <0>;
		qcom,btm-channel-number = <0x88>;
		qcom,thermal-node;
	};
};
